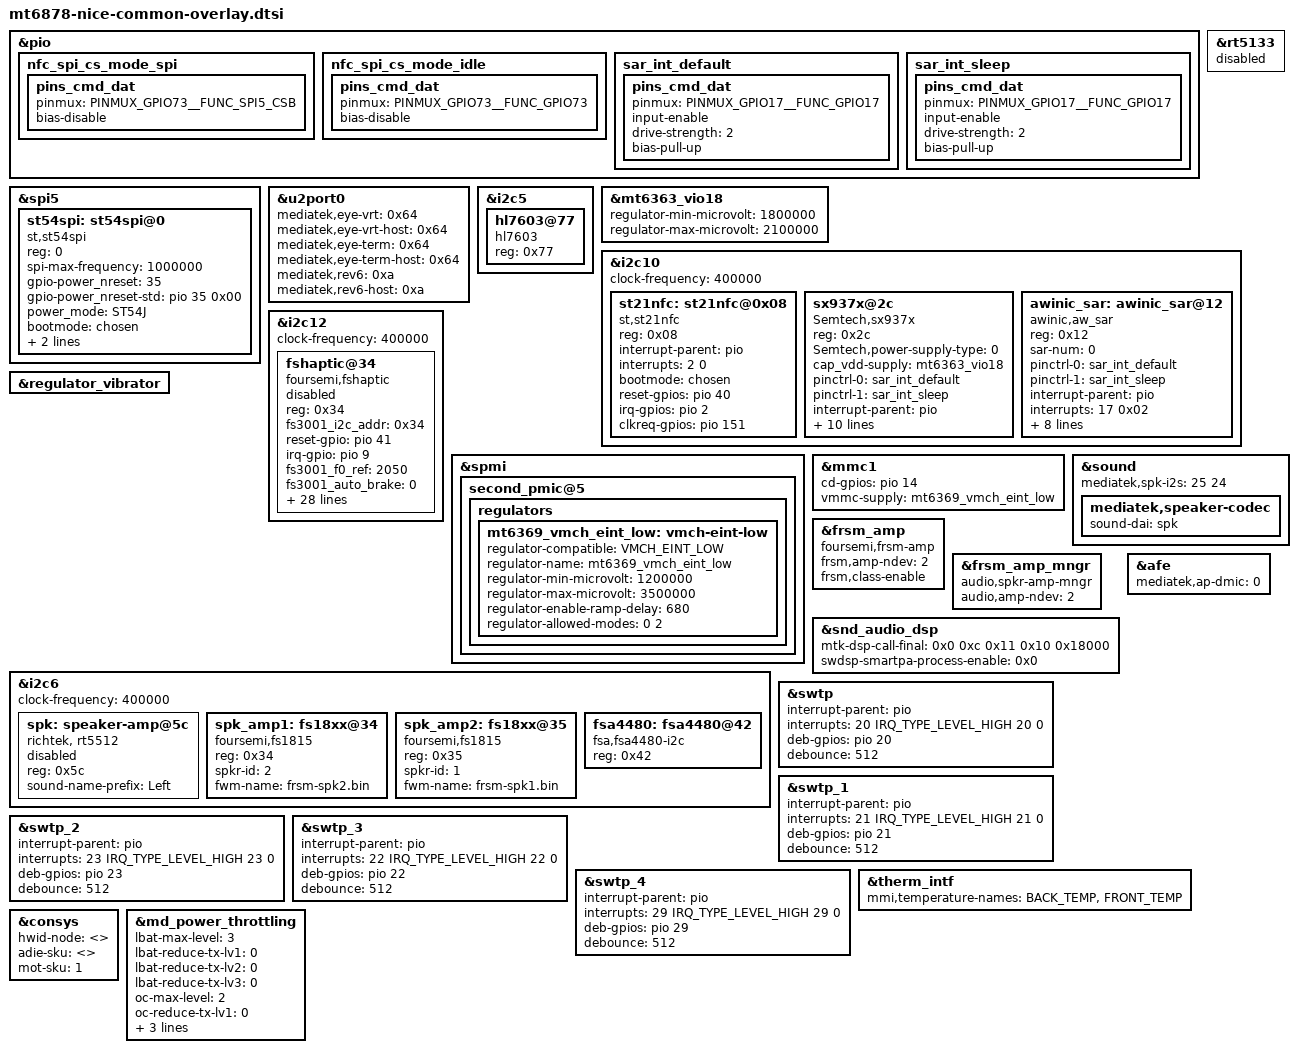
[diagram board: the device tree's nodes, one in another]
/* Copyright (c) 2023, Motorola Mobility Inc. All rights reserved.
 *
 * This program is free software; you can redistribute it and/or modify
 * it under the terms of the GNU General Public License version 2 and
 * only version 2 as published by the Free Software Foundation.
 *
 * This program is distributed in the hope that it will be useful,
 * but WITHOUT ANY WARRANTY; without even the implied warranty of
 * MERCHANTABILITY or FITNESS FOR A PARTICULAR PURPOSE.  See the
 * GNU General Public License for more details.
 */

#include "mediatek/mt6878-moto-common-overlay-single-panel.dtsi"

#include "mediatek/mot-nice-external-camera-pmic.dtsi"
#include "mediatek/cust_nice_camera_v4l2.dtsi"
#include "mediatek/nice-charger.dtsi"
#include "mediatek/nice-fps.dtsi"
#include "mediatek/nice-ntc.dtsi"
#include "mediatek/nice-display.dtsi"
#include "mediatek/nice-touch.dtsi"
#include <dt-bindings/gpio/gpio.h>

&pio {
	nfc_spi_cs_mode_spi: nfc_spi_cs_mode_spi {
		pins_cmd_dat {
			pinmux = <PINMUX_GPIO73__FUNC_SPI5_CSB>;
			bias-disable;
		};
	};

	nfc_spi_cs_mode_idle: nfc_spi_cs_mode_idle {
		pins_cmd_dat {
			pinmux = <PINMUX_GPIO73__FUNC_GPIO73>;
			bias-disable;
		};
	};

	sar_int_default: sar_int_default {
		pins_cmd_dat {
			pinmux = <PINMUX_GPIO17__FUNC_GPIO17>;
			input-enable;
			drive-strength = <2>;
			bias-pull-up;
		};
	};

	sar_int_sleep: sar_int_sleep {
		pins_cmd_dat {
			pinmux = <PINMUX_GPIO17__FUNC_GPIO17>;
			input-enable;
			drive-strength = <2>;
			bias-pull-up;
		};
	};
};


&spi5 {
	st54spi: st54spi@0 {
		compatible = "st,st54spi";
		reg = <0>;
		spi-max-frequency = <1000000>;
		gpio-power_nreset = <35>;
		gpio-power_nreset-std = <&pio 35 0x00>;
		power_mode = "ST54J";
		bootmode = <&chosen>;
		pinctrl-names = "pinctrl_state_mode_spi",
				"pinctrl_state_mode_idle";
		pinctrl-0 = <&nfc_spi_cs_mode_spi>;
		pinctrl-1 = <&nfc_spi_cs_mode_idle>;
		status = "okay";
	};
};

&u2port0{
	mediatek,eye-vrt = <0x64>;
	mediatek,eye-vrt-host = <0x64>;
	mediatek,eye-term = <0x64>;
	mediatek,eye-term-host = <0x64>;
	mediatek,rev6 = <0xa>;
	mediatek,rev6-host = <0xa>;
};

/* BOB */
&i2c5 {
	hl7603@77 {
		status = "ok";
		compatible = "hl7603";
		reg = <0x77>;
		/* hl7603_vout_voltage = <0x0B>; //3.4v */
	};
};


&rt5133 {
	status = "disabled";
};

&mt6363_vio18 {
	regulator-min-microvolt = <1800000>;
	regulator-max-microvolt = <2100000>;
};

&i2c10 {
	clock-frequency = <400000>;
	status = "ok";

	st21nfc: st21nfc@0x08 {
		compatible = "st,st21nfc";
		reg = <0x08>;
		interrupt-parent = <&pio>;
		interrupts = <2 0>;
		bootmode = <&chosen>;
		reset-gpios = <&pio 40 0x00>;
		irq-gpios = <&pio 2 0x00>;
		clkreq-gpios = <&pio 151 0x00>;
		status = "ok";
	};

	sx937x@2c { /* SAR sensor */
		compatible = "Semtech,sx937x";
		reg = <0x2c>;
		Semtech,power-supply-type = <0>;
		cap_vdd-supply = <&mt6363_vio18>;
		pinctrl-names = "default","sleep";
		pinctrl-0 = <&sar_int_default>;
		pinctrl-1 = <&sar_int_sleep>;
		interrupt-parent = <&pio>;
		interrupts = <17 0x02>;
		interrupt-names = "capsense0_irq";
		Semtech,nirq-gpio= <&pio 17 0x02>;
		esd-reinit-on = <1>;
		/*use PH5/6 as the reference sensor
		set it to 0xff if the ref-phases-x is not used*/
		Semtech,ref-phases-a = <5>;
		Semtech,ref-phases-b = <6>;
		Semtech,ref-phases-c = <0xff>;
		Semtech,button-flag = <0x1f>;
		Semtech,reg-num = <61>;
		Semtech,reg-init = <
			0x8024  0x7F7F
			0x4004  0x74
			0x4008  0x8
			0x8020  0x32
			0x8028  0x85E
			0x8034  0x85E
			0x8040  0x85E
			0x804C  0x85E
			0x8058  0x85E
			0x8064  0x85E
			0x8070  0x85E
			0x807C  0x85E
			0x8030  0x924964
			0x803C  0x924925
			0x8048  0x925924
			0x8054  0x92C924
			0x8060  0xB24924
			0x806C  0x92492C
			0x8078  0x964924
			0x8084  0xFFF9FF
			0x8098  0x3737
			0x80B8  0x5F37
			0x80D8  0x3737
			0x80F8  0x5F37
			0x8118  0x3737
			0x8138  0xFF
			0x8158  0xFF
			0x8178  0xFF
			0x80A0  0x20200001
			0x80C0  0x20200001
			0x80E0  0x20200002
			0x8100  0x20200002
			0x8120  0x20200002
			0x8188  0x8000015
			0x818C  0x8000016
			0x8190  0x00
			0x8194  0x00
			0x8090  0x50B85000
			0x80B0  0x50B85000
			0x80D0  0x50B85000
			0x80F0  0x50B85000
			0x8110  0x50B85000
			0x8130  0x5000
			0x8150  0x5000
			0x8170  0x5000
			0x8088  0x300000
			0x80A8  0x300000
			0x80C8  0x300000
			0x80E8  0x300000
			0x8108  0x300000
			0x8128  0x6300000
			0x8148  0x6300000
			0x8168  0x6300000
			0x808C  0x60200030
			0x80AC  0x60200030
			0x80CC  0x60200030
			0x80EC  0x60200030
			0x810C  0x60200030
			0x812C  0x60200030
			0x814C  0x60200030
			0x816C  0x60200030
		>;
		status = "okay";
	};
	awinic_sar:awinic_sar@12 {
			/* common node */
			compatible = "awinic,aw_sar";
			reg = < 0x12 >;
			sar-num = < 0 >;
			pinctrl-names = "default","sleep";
			pinctrl-0 = <&sar_int_default>;
			pinctrl-1 = <&sar_int_sleep>;
			interrupt-parent = <&pio>;
			interrupts = <17 0x02>;
			interrupt-names = "awinic_irq";
			irq-gpio = <&pio 17 0x02>;
			//vcc0-supply = <&mt6363_vio18>;
			channel_use_flag = <0x0f>;
			monitor_esd_flag = <1>;
			aw_sar,use_plug_cail;
			aw_sar,update_fw;
			aw_sar,using_pm_ops;
			/* private node belongs to aw963xx */
			start-mode = < 1 >; // 0: start in rom  1: start in ram
			irq-mux = < 2 >; // set csx as irq pin. config this field when connect to aw96308/aw96310
			status = "okay";
	};
};

&i2c12 {
	clock-frequency = <400000>;
	status = "okay";
		fshaptic@34{
		compatible="foursemi,fshaptic";
		reg=<0x34>;
		fs3001_i2c_addr=<0x34>;
		reset-gpio=<&pio 41 0>;//In pio section, please set the gpio based on the platform
		irq-gpio=<&pio 9 0>;//In pio section, please set the gpio based on the platform

		fs3001_f0_ref=< 2050 >;
		fs3001_auto_brake=< 0 >;
		fs3001_f0_cali_mode=< 1 >;
		fs3001_cont_drv1_lvl=< 127 >;
		fs3001_cont_drv2_lvl=< 54 >;
		fs3001_cont_drv1_time=< 4 >;
		fs3001_cont_drv2_time=< 20 >;
		fs3001_cont_1_period=< 702 >;
		fs3001_brk_slopeth=< 20 >;
		fs3001_brk_gain=< 128 >;
		fs3001_brk_times=< 20 >;
		fs3001_brk_noise_gate=< 32 >;
		fs3001_brk_1_period=< 468 >;
		fs3001_brk_pgagain=< 5 >;
		fs3001_brk_margin=< 48 >;
		fs3001_play_ram_srate=< 0 >;
		fs3001_play_rtp_srate=< 0 >;
		fs3001_lk_f0_cali=< 0 >;
		fs3001_default_vib_mode=< 3 >;
		fs3001_vbat_mode=< 0 >;
		fs3001_bypass_system_gain=< 1 >;
		fs3001_f0_cali_data_mode=< 0 >;
		fs3001_lr_pgagain=< 5 >;
		fs3001_gain_adjust=< 0 >;
		fs3001_rtp_max=< 53 >;
		fs3001_rtp_time=< 20 20 20 >;
		fs3001_reg_inits=< 0xffffff 0xffffff 0xffffff 0xffffff 0xffffff 0xffffff 0xffffff 0xffffff 0xffffff 0xffffff >;
		fs3001_rtp_id_boundary=< 3 >;
		fs3001_duration_time=< 34 67 100 >;
		status = "disabled";
	};
};

&regulator_vibrator {
	status = "okay";
};

&spmi {
	second_pmic@5 {
		regulators {
			mt6369_vmch_eint_low: vmch-eint-low {
				regulator-compatible = "VMCH_EINT_LOW";
				regulator-name = "mt6369_vmch_eint_low";
				regulator-min-microvolt = <1200000>;
				regulator-max-microvolt = <3500000>;
				regulator-enable-ramp-delay = <680>;
				regulator-allowed-modes = <0 2>;
			};
		};
	};
};

&mmc1 {
	status = "ok";
        cd-gpios = <&pio 14 GPIO_ACTIVE_HIGH>;
        vmmc-supply = <&mt6369_vmch_eint_low>;
};

&i2c6 {
 	status = "okay";
	clock-frequency = <400000>;

	spk: speaker-amp@5c {
		compatible = "richtek, rt5512";
		reg = <0x5c>;
		status = "disable";
		sound-name-prefix = "Left";
	};

	spk_amp1: fs18xx@34 {
		compatible = "foursemi,fs1815";
		reg = <0x34>;
		spkr-id = <2>;
		fwm-name = "frsm-spk2.bin";
		status = "okay";
	};

	spk_amp2: fs18xx@35 {
		compatible = "foursemi,fs1815";
		reg = <0x35>;
		spkr-id = <1>;
		fwm-name = "frsm-spk1.bin";
 		status = "okay";
 	};

	fsa4480: fsa4480@42 {
		compatible = "fsa,fsa4480-i2c";
		reg = <0x42>;
		status = "okay";
    };
 };

&sound {
	mediatek,spk-i2s = <25 24>;
	mediatek,speaker-codec {
		sound-dai = <&spk>;
	};
};

&frsm_amp {
	compatible = "foursemi,frsm-amp";
	frsm,amp-ndev = <2>;
	frsm,class-enable;
	status = "okay";
};

&frsm_amp_mngr {
	compatible = "audio,spkr-amp-mngr";
	audio,amp-ndev = <2>;
	status = "okay";
};

&snd_audio_dsp {
	mtk-dsp-call-final = <0x0 0xc 0x11 0x10 0x18000>;
	swdsp-smartpa-process-enable = <0x0>;
};

&afe {
	mediatek,ap-dmic = <0>;
};

&swtp {
	interrupt-parent = <&pio>;
	interrupts = <20 IRQ_TYPE_LEVEL_HIGH 20 0>;
	deb-gpios = <&pio 20 0>;
	debounce = <512>;
	status = "okay";
};

&swtp_1 {
	interrupt-parent = <&pio>;
	interrupts = <21 IRQ_TYPE_LEVEL_HIGH 21 0>;
	deb-gpios = <&pio 21 0>;
	debounce = <512>;
	status = "okay";
};
&swtp_2 {
	interrupt-parent = <&pio>;
	interrupts = <23 IRQ_TYPE_LEVEL_HIGH 23 0>;
	deb-gpios = <&pio 23 0>;
	debounce = <512>;
	status = "okay";
};
&swtp_3 {
	interrupt-parent = <&pio>;
	interrupts = <22 IRQ_TYPE_LEVEL_HIGH 22 0>;
	deb-gpios = <&pio 22 0>;
	debounce = <512>;
	status = "okay";
};
&swtp_4 {
        interrupt-parent = <&pio>;
        interrupts = <29 IRQ_TYPE_LEVEL_HIGH 29 0>;
        deb-gpios = <&pio 29 0>;
        debounce = <512>;
        status = "okay";
};

&therm_intf {
	/*Vsensor name should be CASE DIFFERENT with the name in config file*/
	mmi,temperature-names = "BACK_TEMP", "FRONT_TEMP";/*for "back_temp" in config file*/
};

&consys {
	hwid-node = <>;
	adie-sku = <>;
	mot-sku = <1>;  /* mt6637 = 0, mt6631 = 1 , mt6631 + mt6686 = 2 */
};

&md_power_throttling {
	lbat-max-level = <3>;
	lbat-reduce-tx-lv1 = <0>;
	lbat-reduce-tx-lv2 = <0>;
	lbat-reduce-tx-lv3 = <0>;

	oc-max-level = <2>;
	oc-reduce-tx-lv1 = <0>;
	oc-reduce-tx-lv2 = <0>;

	soc-max-level = <1>;
	soc-reduce-tx-lv1 = <6>;
};
